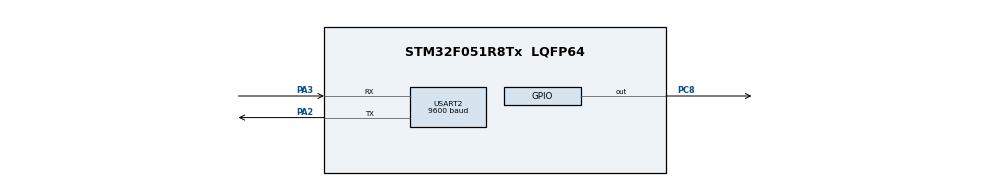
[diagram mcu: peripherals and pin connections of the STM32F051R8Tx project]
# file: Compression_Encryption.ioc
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Mcu.Family=STM32F0
Mcu.Name=STM32F051R8Tx
Mcu.Package=LQFP64
PA2.Mode=Asynchronous
PA2.Signal=USART2_TX
PA3.Mode=Asynchronous
PA3.Signal=USART2_RX
PC8.Signal=GPIO_Output
ProjectManager.HeapSize=0x200
ProjectManager.StackSize=0x400
ProjectManager.TargetToolchain=STM32CubeIDE
USART2.BaudRate=9600
USART2.VirtualMode-Asynchronous=VM_ASYNC
board=custom

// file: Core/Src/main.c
/* USER CODE BEGIN Header */
/**
  ******************************************************************************
  * @file           : main.c
  * @brief          : Main program body
  ******************************************************************************
  * @attention
  *
  * Copyright (c) 2022 STMicroelectronics.
  * All rights reserved.
  *
  * This software is licensed under terms that can be found in the LICENSE file
  * in the root directory of this software component.
  * If no LICENSE file comes with this software, it is provided AS-IS.
  *
  ******************************************************************************
  */
/* USER CODE END Header */
#include "main.h"
#include "heatshrink_encoder.h"

/* USER CODE BEGIN Includes */
//using namespace std;
/* USER CODE END Includes */

UART_HandleTypeDef huart2;

void SystemClock_Config(void);
static void MX_GPIO_Init(void);
static void MX_USART2_UART_Init(void);

int main(void)
{

  /* MCU Configuration--------------------------------------------------------*/

  /* Reset of all peripherals, Initializes the Flash interface and the Systick. */
  HAL_Init();

  /* Configure the system clock */
  SystemClock_Config();

  /* Initialize all configured peripherals */
  MX_GPIO_Init();
  MX_USART2_UART_Init();
  /* USER CODE BEGIN 2 */

	/*uint8_t test[] = {3, 6, 9};

	heatshrink_encoder encoder = *heatshrink_encoder_alloc(8, 4);
	uint8_t* input = test;//START_OF_INPUT_ADRESS;
	size_t size = 2;
	size_t* input_size;
	heatshrink_encoder_sink(&encoder, input, size, input_size);

	uint8_t* out_buf;
	size_t out_buf_size = 2;
	size_t* output_size;
	heatshrink_encoder_poll(&encoder, out_buf, out_buf_size, output_size);

	uint8_t num = 3;
	uint8_t* ptr = &num;*/

  /*uint8_t val = 0;
  uint8_t* buffer = &val;*/
  char buffer[4];
  //*buffer = 0;

	sprintf(buffer, "%d \r\n", 6);

  	/*buffer_val = "hello";
  	buffer = &buffer_val;*/

  /*uint8_t i = 92;
  uint8_t* p = &i;*/

	HAL_I2C_Mem_Read(hi2c, DevAddress, MemAddress, MemAddSize, pData, Size, Timeout)

  /* USER CODE END 2 */

  /* Infinite loop */
  while (1)
  {
	HAL_GPIO_TogglePin(GPIOC, GPIO_PIN_8);

	HAL_UART_Transmit(&huart2, buffer, sizeof(buffer), 1000);
	//HAL_UART_Transmit(&huart2, p, sizeof(p), 1000);

	for (int i = 0; i < 1234567; i++);
  }
}

void SystemClock_Config(void)
{
  RCC_OscInitTypeDef RCC_OscInitStruct = {0};
  RCC_ClkInitTypeDef RCC_ClkInitStruct = {0};

  /** Initializes the RCC Oscillators according to the specified parameters
  * in the RCC_OscInitTypeDef structure.
  */
  RCC_OscInitStruct.OscillatorType = RCC_OSCILLATORTYPE_HSI;
  RCC_OscInitStruct.HSIState = RCC_HSI_ON;
  RCC_OscInitStruct.HSICalibrationValue = RCC_HSICALIBRATION_DEFAULT;
  RCC_OscInitStruct.PLL.PLLState = RCC_PLL_NONE;
  if (HAL_RCC_OscConfig(&RCC_OscInitStruct) != HAL_OK)
  {
    Error_Handler();
  }

  /** Initializes the CPU, AHB and APB buses clocks
  */
  RCC_ClkInitStruct.ClockType = RCC_CLOCKTYPE_HCLK|RCC_CLOCKTYPE_SYSCLK
                              |RCC_CLOCKTYPE_PCLK1;
  RCC_ClkInitStruct.SYSCLKSource = RCC_SYSCLKSOURCE_HSI;
  RCC_ClkInitStruct.AHBCLKDivider = RCC_SYSCLK_DIV1;
  RCC_ClkInitStruct.APB1CLKDivider = RCC_HCLK_DIV1;

  if (HAL_RCC_ClockConfig(&RCC_ClkInitStruct, FLASH_LATENCY_0) != HAL_OK)
  {
    Error_Handler();
  }
}

static void MX_USART2_UART_Init(void)
{

  huart2.Instance = USART2;
  huart2.Init.BaudRate = 9600;
  huart2.Init.WordLength = UART_WORDLENGTH_8B;
  huart2.Init.StopBits = UART_STOPBITS_1;
  huart2.Init.Parity = UART_PARITY_NONE;
  huart2.Init.Mode = UART_MODE_TX_RX;
  huart2.Init.HwFlowCtl = UART_HWCONTROL_NONE;
  huart2.Init.OverSampling = UART_OVERSAMPLING_16;
  huart2.Init.OneBitSampling = UART_ONE_BIT_SAMPLE_DISABLE;
  huart2.AdvancedInit.AdvFeatureInit = UART_ADVFEATURE_NO_INIT;
  if (HAL_UART_Init(&huart2) != HAL_OK)
  {
    Error_Handler();
  }

}

static void MX_GPIO_Init(void)
{
  GPIO_InitTypeDef GPIO_InitStruct = {0};

  /* GPIO Ports Clock Enable */
  __HAL_RCC_GPIOA_CLK_ENABLE();
  __HAL_RCC_GPIOC_CLK_ENABLE();

  /*Configure GPIO pin Output Level */
  HAL_GPIO_WritePin(GPIOC, GPIO_PIN_8, GPIO_PIN_RESET);

  /*Configure GPIO pin : PC8 */
  GPIO_InitStruct.Pin = GPIO_PIN_8;
  GPIO_InitStruct.Mode = GPIO_MODE_OUTPUT_PP;
  GPIO_InitStruct.Pull = GPIO_NOPULL;
  GPIO_InitStruct.Speed = GPIO_SPEED_FREQ_LOW;
  HAL_GPIO_Init(GPIOC, &GPIO_InitStruct);

}

void Error_Handler(void)
{
  __disable_irq();
  while (1)
  {
  }
}
